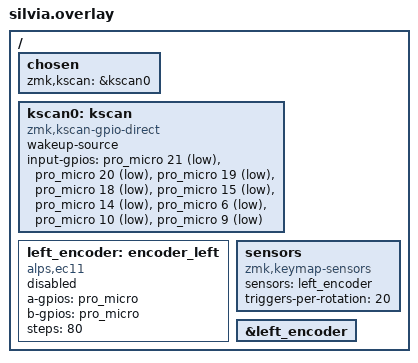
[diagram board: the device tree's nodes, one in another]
/*
 * Copyright (c) 2022 The ZMK Contributors
 *
 * SPDX-License-Identifier: MIT
 */

/ {
    chosen {
        zmk,kscan = &kscan0;
    };

    kscan0: kscan {
        compatible = "zmk,kscan-gpio-direct";
        wakeup-source;
        input-gpios
            = <&pro_micro 21 (GPIO_ACTIVE_LOW | GPIO_PULL_UP)>
            , <&pro_micro 20 (GPIO_ACTIVE_LOW | GPIO_PULL_UP)>
            , <&pro_micro 19 (GPIO_ACTIVE_LOW | GPIO_PULL_UP)>
            , <&pro_micro 18 (GPIO_ACTIVE_LOW | GPIO_PULL_UP)>
            , <&pro_micro 15 (GPIO_ACTIVE_LOW | GPIO_PULL_UP)>
            , <&pro_micro 14 (GPIO_ACTIVE_LOW | GPIO_PULL_UP)>
            , <&pro_micro 6  (GPIO_ACTIVE_LOW | GPIO_PULL_UP)>
            , <&pro_micro 10 (GPIO_ACTIVE_LOW | GPIO_PULL_UP)>
            , <&pro_micro 9  (GPIO_ACTIVE_LOW | GPIO_PULL_UP)>
            ;

    };
        left_encoder: encoder_left {
        compatible = "alps,ec11";
        a-gpios = <&pro_micro 8(GPIO_ACTIVE_HIGH | GPIO_PULL_UP)>;
        b-gpios = <&pro_micro 7(GPIO_ACTIVE_HIGH | GPIO_PULL_UP)>;
        steps = <80>;
        status = "disabled";
    };
        sensors: sensors {
        compatible = "zmk,keymap-sensors";
        sensors = <&left_encoder>;
        triggers-per-rotation = <20>;
    };
    &left_encoder {
    status = "okay";
};

};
